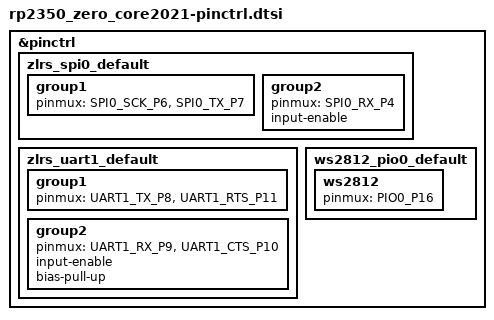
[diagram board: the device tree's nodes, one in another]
/*
 * Copyright (c) 2026 zlrs contributors
 * SPDX-License-Identifier: Apache-2.0
 */

#include <zephyr/dt-bindings/pinctrl/rpi-pico-pinctrl-common.h>
#include <zephyr/dt-bindings/pinctrl/rpi-pico-rp2350a-pinctrl.h>

&pinctrl {
	/* Radio SPI0: stays clear of GP16, the on-board WS2812B data pin */
	zlrs_spi0_default: zlrs_spi0_default {
		group1 {
			pinmux = <SPI0_SCK_P6>, <SPI0_TX_P7>;
		};

		group2 {
			pinmux = <SPI0_RX_P4>;
			input-enable;
		};
	};

	/* Data UART: the passthrough port */
	zlrs_uart1_default: zlrs_uart1_default {
		group1 {
			pinmux = <UART1_TX_P8>, <UART1_RTS_P11>;
		};

		group2 {
			pinmux = <UART1_RX_P9>, <UART1_CTS_P10>;
			input-enable;
			/* RX idles high; disconnected CTS prevents transmitting to an absent host. */
			bias-pull-up;
		};
	};

	/* The on-board WS2812B data pin (GP16) goes to PIO0, wired as on the upstream waveshare board */
	ws2812_pio0_default: ws2812_pio0_default {
		ws2812 {
			pinmux = <PIO0_P16>;
		};
	};
};
